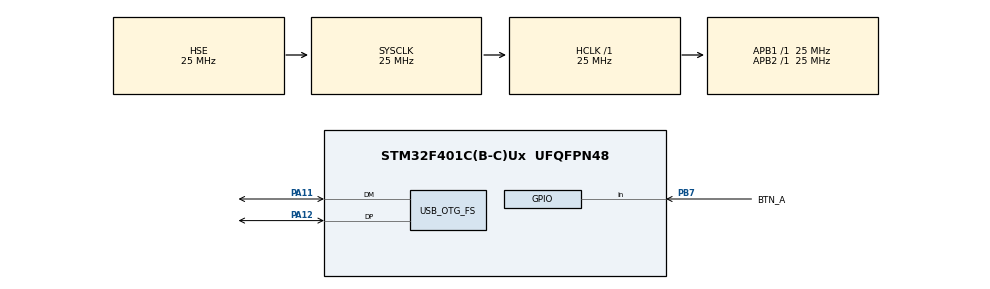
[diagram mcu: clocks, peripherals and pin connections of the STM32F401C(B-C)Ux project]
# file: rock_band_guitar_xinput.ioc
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Mcu.Family=STM32F4
Mcu.Name=STM32F401C(B-C)Ux
Mcu.Package=UFQFPN48
NVIC.OTG_FS_IRQn=true\:0\:0\:false\:false\:true\:true\:true\:true
NVIC.PriorityGroup=NVIC_PRIORITYGROUP_4
PA11.Mode=Device_Only
PA11.Signal=USB_OTG_FS_DM
PA12.Mode=Device_Only
PA12.Signal=USB_OTG_FS_DP
PA13.Mode=Trace_Asynchronous_SW
PA13.Signal=SYS_JTMS-SWDIO
PA14.Mode=Trace_Asynchronous_SW
PA14.Signal=SYS_JTCK-SWCLK
PB3.Mode=Trace_Asynchronous_SW
PB3.Signal=SYS_JTDO-SWO
PB7.GPIO_Label=BTN_A
PB7.GPIO_PuPd=GPIO_PULLUP
PB7.Signal=GPIO_Input
PH0\ -\ OSC_IN.Mode=HSE-External-Oscillator
PH0\ -\ OSC_IN.Signal=RCC_OSC_IN
PH1\ -\ OSC_OUT.Mode=HSE-External-Oscillator
PH1\ -\ OSC_OUT.Signal=RCC_OSC_OUT
ProjectManager.HeapSize=0x200
ProjectManager.StackSize=0x400
ProjectManager.TargetToolchain=STM32CubeIDE
RCC.48MHZClocksFreq_Value=48000000
RCC.AHBFreq_Value=25000000
RCC.APB1Freq_Value=25000000
RCC.APB1TimFreq_Value=25000000
RCC.APB2Freq_Value=25000000
RCC.APB2TimFreq_Value=25000000
RCC.CortexFreq_Value=25000000
RCC.HCLKFreq_Value=25000000
RCC.HSE_VALUE=25000000
RCC.HSI_VALUE=16000000
RCC.LSE_VALUE=32768
RCC.PLLM=15
RCC.PLLN=144
RCC.PLLQ=5
RCC.SYSCLKFreq_VALUE=25000000
RCC.SYSCLKSource=RCC_SYSCLKSOURCE_HSE
RCC.VCOOutputFreq_Value=240000000
USB_OTG_FS.VirtualMode=Device_Only
board=custom

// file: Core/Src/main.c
/* USER CODE BEGIN Header */
/**
  ******************************************************************************
  * @file           : main.c
  * @brief          : Main program body
  ******************************************************************************
  * @attention
  *
  * Copyright (c) 2025 STMicroelectronics.
  * All rights reserved.
  *
  * This software is licensed under terms that can be found in the LICENSE file
  * in the root directory of this software component.
  * If no LICENSE file comes with this software, it is provided AS-IS.
  *
  ******************************************************************************
  */
/* USER CODE END Header */
#include <rb_guitar.h>
#include <usb_device.h>
#include "main.h"

/* USER CODE BEGIN Includes */
#include "tusb.h"
#include "device/usbd_pvt.h"
#include "xinput_device.h"
/* USER CODE END Includes */

PCD_HandleTypeDef hpcd_USB_OTG_FS;

/* USER CODE BEGIN PV */
uint8_t lastPlayer = 0;
/* USER CODE END PV */

void SystemClock_Config(void);
static void MX_GPIO_Init(void);
static void MX_USB_OTG_FS_PCD_Init(void);
/* USER CODE BEGIN PFP */
static void sendReportData(void);
/* USER CODE END PFP */

/* USER CODE BEGIN 0 */
typedef struct {
	uint8_t rid;
	uint8_t rsize;
	uint16_t buttons;
	uint8_t lt;
	uint8_t rt;
	int l_x;
	int l_y;
	int r_x;
	int r_y;
	uint8_t reserved_1[6];
} ReportDataXinput_t;

ReportDataXinput_t txData;
/* USER CODE END 0 */

int main(void)
{

  /* MCU Configuration--------------------------------------------------------*/

  /* Reset of all peripherals, Initializes the Flash interface and the Systick. */
  HAL_Init();

  /* Configure the system clock */
  SystemClock_Config();

  /* Initialize all configured peripherals */
  MX_GPIO_Init();
  MX_USB_OTG_FS_PCD_Init();
  /* USER CODE BEGIN 2 */
  tusb_init(BOARD_TUD_RHPORT);
  /* USER CODE END 2 */

  /* Infinite loop */
  /* USER CODE BEGIN WHILE */
  while (1)
  {

	  txData.buttons = 0;	//Clear all buttons states
	  txData.buttons |= !HAL_GPIO_ReadPin(BTN_A_GPIO_Port, BTN_A_Pin) << XBOX_A; // A Button
	  tud_task();
	  sendReportData();
	  if(lastPlayer != playerLedValue()){
		  //printf("%d\n", playerLedValue());
		  lastPlayer = playerLedValue();
	  }
    /* USER CODE END WHILE */

  }
}

void SystemClock_Config(void)
{
  RCC_OscInitTypeDef RCC_OscInitStruct = {0};
  RCC_ClkInitTypeDef RCC_ClkInitStruct = {0};

  /** Configure the main internal regulator output voltage
  */
  __HAL_RCC_PWR_CLK_ENABLE();
  __HAL_PWR_VOLTAGESCALING_CONFIG(PWR_REGULATOR_VOLTAGE_SCALE2);

  /** Initializes the RCC Oscillators according to the specified parameters
  * in the RCC_OscInitTypeDef structure.
  */
  RCC_OscInitStruct.OscillatorType = RCC_OSCILLATORTYPE_HSE;
  RCC_OscInitStruct.HSEState = RCC_HSE_ON;
  RCC_OscInitStruct.PLL.PLLState = RCC_PLL_ON;
  RCC_OscInitStruct.PLL.PLLSource = RCC_PLLSOURCE_HSE;
  RCC_OscInitStruct.PLL.PLLM = 15;
  RCC_OscInitStruct.PLL.PLLN = 144;
  RCC_OscInitStruct.PLL.PLLP = RCC_PLLP_DIV2;
  RCC_OscInitStruct.PLL.PLLQ = 5;
  if (HAL_RCC_OscConfig(&RCC_OscInitStruct) != HAL_OK)
  {
    Error_Handler();
  }

  /** Initializes the CPU, AHB and APB buses clocks
  */
  RCC_ClkInitStruct.ClockType = RCC_CLOCKTYPE_HCLK|RCC_CLOCKTYPE_SYSCLK
                              |RCC_CLOCKTYPE_PCLK1|RCC_CLOCKTYPE_PCLK2;
  RCC_ClkInitStruct.SYSCLKSource = RCC_SYSCLKSOURCE_HSE;
  RCC_ClkInitStruct.AHBCLKDivider = RCC_SYSCLK_DIV1;
  RCC_ClkInitStruct.APB1CLKDivider = RCC_HCLK_DIV1;
  RCC_ClkInitStruct.APB2CLKDivider = RCC_HCLK_DIV1;

  if (HAL_RCC_ClockConfig(&RCC_ClkInitStruct, FLASH_LATENCY_0) != HAL_OK)
  {
    Error_Handler();
  }
}

static void MX_USB_OTG_FS_PCD_Init(void)
{

  hpcd_USB_OTG_FS.Instance = USB_OTG_FS;
  hpcd_USB_OTG_FS.Init.dev_endpoints = 4;
  hpcd_USB_OTG_FS.Init.speed = PCD_SPEED_FULL;
  hpcd_USB_OTG_FS.Init.dma_enable = DISABLE;
  hpcd_USB_OTG_FS.Init.phy_itface = PCD_PHY_EMBEDDED;
  hpcd_USB_OTG_FS.Init.Sof_enable = DISABLE;
  hpcd_USB_OTG_FS.Init.low_power_enable = DISABLE;
  hpcd_USB_OTG_FS.Init.lpm_enable = DISABLE;
  hpcd_USB_OTG_FS.Init.vbus_sensing_enable = DISABLE;
  hpcd_USB_OTG_FS.Init.use_dedicated_ep1 = DISABLE;
  if (HAL_PCD_Init(&hpcd_USB_OTG_FS) != HAL_OK)
  {
    Error_Handler();
  }

}

static void MX_GPIO_Init(void)
{
  GPIO_InitTypeDef GPIO_InitStruct = {0};

  /* GPIO Ports Clock Enable */
  __HAL_RCC_GPIOH_CLK_ENABLE();
  __HAL_RCC_GPIOA_CLK_ENABLE();
  __HAL_RCC_GPIOB_CLK_ENABLE();

  /*Configure GPIO pin : BTN_A_Pin */
  GPIO_InitStruct.Pin = BTN_A_Pin;
  GPIO_InitStruct.Mode = GPIO_MODE_INPUT;
  GPIO_InitStruct.Pull = GPIO_PULLUP;
  HAL_GPIO_Init(BTN_A_GPIO_Port, &GPIO_InitStruct);

}

/* USER CODE BEGIN 4 */

usbd_class_driver_t driver[] = {
    {
#if CFG_TUSB_DEBUG >= 2
        .name = "Xinput_Driver",
#endif
        .init = xinputd_init,
        .reset = xinputd_reset,
        .open = xinputd_open,
        .control_xfer_cb = tud_vendor_control_xfer_cb,
        .xfer_cb = xinputd_xfer_cb,
        .sof = NULL}};

usbd_class_driver_t const *usbd_app_driver_get_cb(uint8_t *driver_count)
{
    *driver_count = 1;
    return driver;
}

int _write(int file, char *ptr, int len)
{
    for (int i = 0; i < len; i++)
    {
        ITM_SendChar(*ptr++);
    }
    return len;
}

static void sendReportData(void) {

  // Poll every 1ms
    const uint32_t interval_ms = 1;
    static uint32_t start_ms = 0;

    if (HAL_GetTick() - start_ms < interval_ms) return;  // not enough time
    start_ms += interval_ms;

    if (!tud_ready()) return;
    txData.rsize = 20;
	tud_xinput_n_report(0, 0, &txData, txData.rsize);
}
/* USER CODE END 4 */

void Error_Handler(void)
{
  __disable_irq();
  while (1)
  {
  }
}
